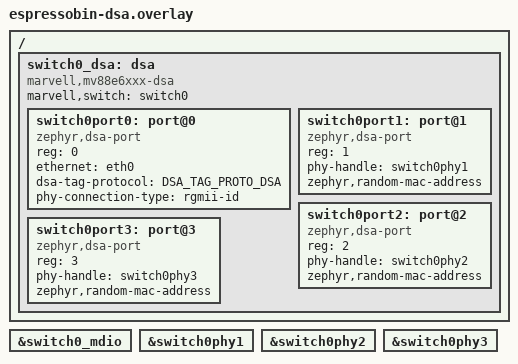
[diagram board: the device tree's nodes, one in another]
/*
 * Copyright (c) 2026 Jiri Kastner
 * SPDX-License-Identifier: Apache-2.0
 *
 * 88E6341 as a DSA switch: eth0 is the conduit, ports 1-3 get their own
 * interfaces (swpN, in port order after the CPU port).
 */

#include <zephyr/dt-bindings/ethernet/dsa_tag_proto.h>

&switch0_mdio {
	status = "okay";
};

&switch0phy1 {
	status = "okay";
};

&switch0phy2 {
	status = "okay";
};

&switch0phy3 {
	status = "okay";
};

/ {
	switch0_dsa: dsa {
		compatible = "marvell,mv88e6xxx-dsa";
		marvell,switch = <&switch0>;
		#address-cells = <1>;
		#size-cells = <0>;

		switch0port0: port@0 {
			compatible = "zephyr,dsa-port";
			reg = <0>;
			ethernet = <&eth0>;
			dsa-tag-protocol = <DSA_TAG_PROTO_DSA>;
			phy-connection-type = "rgmii-id";
		};

		switch0port1: port@1 {
			compatible = "zephyr,dsa-port";
			reg = <1>;
			phy-handle = <&switch0phy1>;
			zephyr,random-mac-address;
		};

		switch0port2: port@2 {
			compatible = "zephyr,dsa-port";
			reg = <2>;
			phy-handle = <&switch0phy2>;
			zephyr,random-mac-address;
		};

		switch0port3: port@3 {
			compatible = "zephyr,dsa-port";
			reg = <3>;
			phy-handle = <&switch0phy3>;
			zephyr,random-mac-address;
		};
	};
};
